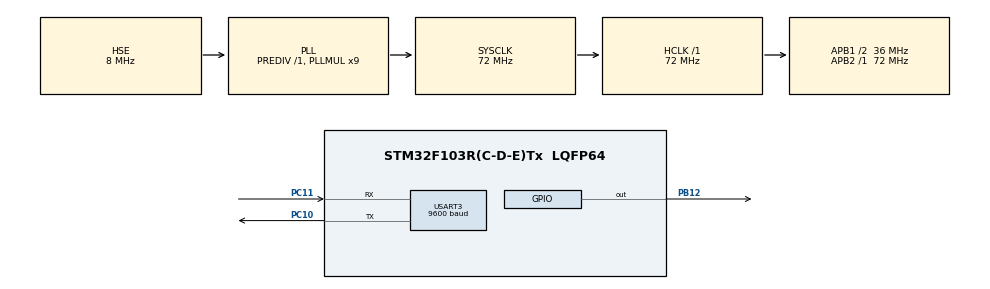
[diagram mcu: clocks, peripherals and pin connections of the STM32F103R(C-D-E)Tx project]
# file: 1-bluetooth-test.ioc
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Mcu.Family=STM32F1
Mcu.Name=STM32F103R(C-D-E)Tx
Mcu.Package=LQFP64
NVIC.PriorityGroup=NVIC_PRIORITYGROUP_4
NVIC.USART3_IRQn=true\:0\:0\:false\:false\:true\:true\:true\:true
PA13.Mode=Serial_Wire
PA13.Signal=SYS_JTMS-SWDIO
PA14.Mode=Serial_Wire
PA14.Signal=SYS_JTCK-SWCLK
PB12.Signal=GPIO_Output
PC10.Mode=Asynchronous
PC10.Signal=USART3_TX
PC11.Mode=Asynchronous
PC11.Signal=USART3_RX
PD0-OSC_IN.Mode=HSE-External-Oscillator
PD0-OSC_IN.Signal=RCC_OSC_IN
PD1-OSC_OUT.Mode=HSE-External-Oscillator
PD1-OSC_OUT.Signal=RCC_OSC_OUT
ProjectManager.HeapSize=0x200
ProjectManager.StackSize=0x400
ProjectManager.TargetToolchain=STM32CubeIDE
RCC.AHBFreq_Value=72000000
RCC.APB1CLKDivider=RCC_HCLK_DIV2
RCC.APB1Freq_Value=36000000
RCC.APB1TimFreq_Value=72000000
RCC.APB2Freq_Value=72000000
RCC.APB2TimFreq_Value=72000000
RCC.HCLKFreq_Value=72000000
RCC.PLLMUL=RCC_PLL_MUL9
RCC.PLLSourceVirtual=RCC_PLLSOURCE_HSE
RCC.SYSCLKFreq_VALUE=72000000
RCC.SYSCLKSource=RCC_SYSCLKSOURCE_PLLCLK
RCC.USBFreq_Value=72000000
USART3.BaudRate=9600
USART3.VirtualMode=VM_ASYNC
board=custom

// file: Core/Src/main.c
/* USER CODE BEGIN Header */
/**
  ******************************************************************************
  * @file           : main.c
  * @brief          : Main program body
  ******************************************************************************
  * @attention
  *
  * Copyright (c) 2026 STMicroelectronics.
  * All rights reserved.
  *
  * This software is licensed under terms that can be found in the LICENSE file
  * in the root directory of this software component.
  * If no LICENSE file comes with this software, it is provided AS-IS.
  *
  ******************************************************************************
  */
/* USER CODE END Header */
#include "main.h"

UART_HandleTypeDef huart3;

/* USER CODE BEGIN PV */
uint8_t rx_buf[1];           // single byte RX buffer
uint8_t rx_data[64];         // accumulated receive buffer
uint8_t rx_index = 0;
uint8_t tx_buf[128];         // transmit buffer
uint32_t uart_tick = 0;
/* USER CODE END PV */

void SystemClock_Config(void);
static void MX_GPIO_Init(void);
static void MX_USART3_UART_Init(void);

int main(void)
{

  /* MCU Configuration--------------------------------------------------------*/

  /* Reset of all peripherals, Initializes the Flash interface and the Systick. */
  HAL_Init();

  /* Configure the system clock */
  SystemClock_Config();

  /* Initialize all configured peripherals */
  MX_GPIO_Init();
  MX_USART3_UART_Init();
  /* USER CODE BEGIN 2 */
  HAL_DBGMCU_EnableDBGSleepMode();
  HAL_DBGMCU_EnableDBGStopMode();
  HAL_DBGMCU_EnableDBGStandbyMode();

  // Start UART receive interrupt — 1 byte at a time
  HAL_UART_Receive_IT(&huart3, rx_buf, 1);

  // Send boot message
//  char *boot_msg = "GIMBAL BOOT OK\r\n";
//  HAL_UART_Transmit(&huart3, (uint8_t*)boot_msg, strlen(boot_msg), 100);

  uart_tick = HAL_GetTick();
  /* USER CODE END 2 */

  /* Infinite loop */
  while (1)
  {

    /* USER CODE BEGIN 3 */
	  HAL_UART_Transmit(&huart3, (uint8_t*)"JDY23 OK\r\n", 10, 100);
	  // Send heartbeat every 1 second
	  if (HAL_GetTick() - uart_tick >= 1000)
	  {
	      // Blink LED0 to show loop is alive
	      HAL_GPIO_TogglePin(GPIOB, GPIO_PIN_12);

	      // Send status over Bluetooth
	      int len = snprintf((char*)tx_buf, sizeof(tx_buf),
	                         "TICK: %lu ms | LED: OK\r\n",
	                         HAL_GetTick());
//	      HAL_UART_Transmit(&huart3, tx_buf, len, 100);

	      uart_tick = HAL_GetTick();
	  }
	  // Send heartbeat every 1 second
	  if (HAL_GetTick() - uart_tick >= 1000)
	  {
	      // Blink LED0 to show loop is alive
	      HAL_GPIO_TogglePin(GPIOB, GPIO_PIN_12);

	      // Send status over Bluetooth
	      int len = snprintf((char*)tx_buf, sizeof(tx_buf),
	                         "TICK: %lu ms | LED: OK\r\n",
	                         HAL_GetTick());
//	      HAL_UART_Transmit(&huart3, tx_buf, len, 100);

	      uart_tick = HAL_GetTick();
	  }

  }
  /* USER CODE END 3 */
}

void SystemClock_Config(void)
{
  RCC_OscInitTypeDef RCC_OscInitStruct = {0};
  RCC_ClkInitTypeDef RCC_ClkInitStruct = {0};

  /** Initializes the RCC Oscillators according to the specified parameters
  * in the RCC_OscInitTypeDef structure.
  */
  RCC_OscInitStruct.OscillatorType = RCC_OSCILLATORTYPE_HSE;
  RCC_OscInitStruct.HSEState = RCC_HSE_ON;
  RCC_OscInitStruct.HSEPredivValue = RCC_HSE_PREDIV_DIV1;
  RCC_OscInitStruct.HSIState = RCC_HSI_ON;
  RCC_OscInitStruct.PLL.PLLState = RCC_PLL_ON;
  RCC_OscInitStruct.PLL.PLLSource = RCC_PLLSOURCE_HSE;
  RCC_OscInitStruct.PLL.PLLMUL = RCC_PLL_MUL9;
  if (HAL_RCC_OscConfig(&RCC_OscInitStruct) != HAL_OK)
  {
    Error_Handler();
  }

  /** Initializes the CPU, AHB and APB buses clocks
  */
  RCC_ClkInitStruct.ClockType = RCC_CLOCKTYPE_HCLK|RCC_CLOCKTYPE_SYSCLK
                              |RCC_CLOCKTYPE_PCLK1|RCC_CLOCKTYPE_PCLK2;
  RCC_ClkInitStruct.SYSCLKSource = RCC_SYSCLKSOURCE_PLLCLK;
  RCC_ClkInitStruct.AHBCLKDivider = RCC_SYSCLK_DIV1;
  RCC_ClkInitStruct.APB1CLKDivider = RCC_HCLK_DIV2;
  RCC_ClkInitStruct.APB2CLKDivider = RCC_HCLK_DIV1;

  if (HAL_RCC_ClockConfig(&RCC_ClkInitStruct, FLASH_LATENCY_2) != HAL_OK)
  {
    Error_Handler();
  }
}

static void MX_USART3_UART_Init(void)
{

  huart3.Instance = USART3;
  huart3.Init.BaudRate = 9600;
  huart3.Init.WordLength = UART_WORDLENGTH_8B;
  huart3.Init.StopBits = UART_STOPBITS_1;
  huart3.Init.Parity = UART_PARITY_NONE;
  huart3.Init.Mode = UART_MODE_TX_RX;
  huart3.Init.HwFlowCtl = UART_HWCONTROL_NONE;
  huart3.Init.OverSampling = UART_OVERSAMPLING_16;
  if (HAL_UART_Init(&huart3) != HAL_OK)
  {
    Error_Handler();
  }

}

static void MX_GPIO_Init(void)
{
  GPIO_InitTypeDef GPIO_InitStruct = {0};

  /* GPIO Ports Clock Enable */
  __HAL_RCC_GPIOD_CLK_ENABLE();
  __HAL_RCC_GPIOB_CLK_ENABLE();
  __HAL_RCC_GPIOA_CLK_ENABLE();
  __HAL_RCC_GPIOC_CLK_ENABLE();

  /*Configure GPIO pin Output Level */
  HAL_GPIO_WritePin(GPIOB, GPIO_PIN_12, GPIO_PIN_RESET);

  /*Configure GPIO pin : PB12 */
  GPIO_InitStruct.Pin = GPIO_PIN_12;
  GPIO_InitStruct.Mode = GPIO_MODE_OUTPUT_PP;
  GPIO_InitStruct.Pull = GPIO_NOPULL;
  GPIO_InitStruct.Speed = GPIO_SPEED_FREQ_LOW;
  HAL_GPIO_Init(GPIOB, &GPIO_InitStruct);

}

/* USER CODE BEGIN 4 */
// Called every time 1 byte is received
void HAL_UART_RxCpltCallback(UART_HandleTypeDef *huart)
{
    if (huart->Instance == USART3)
    {
        // Echo byte back
//        HAL_UART_Transmit(&huart3, rx_buf, 1, 10);

        // Accumulate into buffer
        if (rx_buf[0] == '\n' || rx_index >= sizeof(rx_data) - 1)
        {
            // Process command
            rx_data[rx_index] = '\0';

            // Simple command handler
            if (strncmp((char*)rx_data, "LED1", 4) == 0)
            {
                HAL_GPIO_TogglePin(GPIOB, GPIO_PIN_12);
//                HAL_UART_Transmit(&huart3, (uint8_t*)"LED1 TOGGLED\r\n", 14, 10);
            }
            else if (strncmp((char*)rx_data, "LED2", 4) == 0)
            {
                HAL_GPIO_TogglePin(GPIOB, GPIO_PIN_13);
//                HAL_UART_Transmit(&huart3, (uint8_t*)"LED2 TOGGLED\r\n", 14, 10);
            }
            else if (strncmp((char*)rx_data, "STATUS", 6) == 0)
            {
                int len = snprintf((char*)tx_buf, sizeof(tx_buf),
                                   "STATUS: Running | Tick=%lu\r\n",
                                   HAL_GetTick());
//                HAL_UART_Transmit(&huart3, tx_buf, len, 10);
            }

            rx_index = 0;  // reset buffer
        }
        else
        {
            rx_data[rx_index++] = rx_buf[0];
        }

        // Re-arm interrupt for next byte
        HAL_UART_Receive_IT(&huart3, rx_buf, 1);
    }
}
/* USER CODE END 4 */

void Error_Handler(void)
{
  __disable_irq();
  while (1)
  {
  }
}
